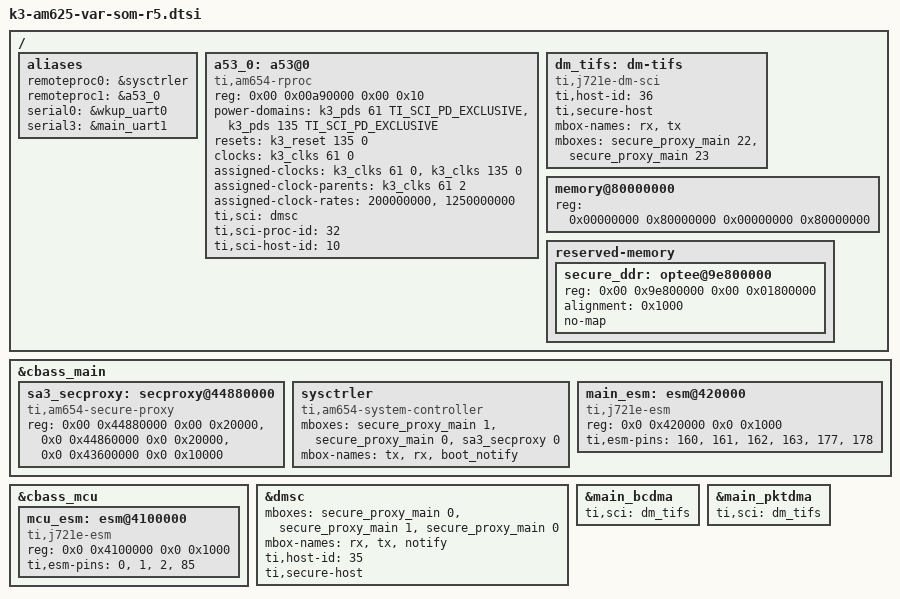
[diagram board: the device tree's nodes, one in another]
// SPDX-License-Identifier: GPL-2.0
/*
 * dtsi file for R5 SPL for VAR-SOM-AM62 and derivatives
 * Copyright (C) 2021-2022 Texas Instruments Incorporated - https://www.ti.com/
 * Copyright (C) 2023-2024 Variscite Ltd. - https://www.variscite.com/
 */

/ {
	aliases {
		remoteproc0 = &sysctrler;
		remoteproc1 = &a53_0;
		serial0 = &wkup_uart0;
		serial3 = &main_uart1;
	};

	a53_0: a53@0 {
		compatible = "ti,am654-rproc";
		reg = <0x00 0x00a90000 0x00 0x10>;
		power-domains = <&k3_pds 61 TI_SCI_PD_EXCLUSIVE>,
				<&k3_pds 135 TI_SCI_PD_EXCLUSIVE>;
		resets = <&k3_reset 135 0>;
		clocks = <&k3_clks 61 0>;
		assigned-clocks = <&k3_clks 61 0>, <&k3_clks 135 0>;
		assigned-clock-parents = <&k3_clks 61 2>;
		assigned-clock-rates = <200000000>, <1250000000>;
		ti,sci = <&dmsc>;
		ti,sci-proc-id = <32>;
		ti,sci-host-id = <10>;
		bootph-pre-ram;
	};

	dm_tifs: dm-tifs {
		compatible = "ti,j721e-dm-sci";
		ti,host-id = <36>;
		ti,secure-host;
		mbox-names = "rx", "tx";
		mboxes= <&secure_proxy_main 22>,
			<&secure_proxy_main 23>;
		bootph-pre-ram;
	};

	memory@80000000 {
		device_type = "memory";
		/* 2G RAM */
		reg = <0x00000000 0x80000000 0x00000000 0x80000000>;

		bootph-pre-ram;
	};

	reserved-memory {
		#address-cells = <2>;
		#size-cells = <2>;
		ranges;

		secure_ddr: optee@9e800000 {
			reg = <0x00 0x9e800000 0x00 0x01800000>; /* for OP-TEE */
			alignment = <0x1000>;
			no-map;
		};
	};
};

&cbass_main {
	sa3_secproxy: secproxy@44880000 {
		bootph-pre-ram;
		compatible = "ti,am654-secure-proxy";
		#mbox-cells = <1>;
		reg-names = "rt", "scfg", "target_data";
		reg = <0x00 0x44880000 0x00 0x20000>,
		      <0x0 0x44860000 0x0 0x20000>,
		      <0x0 0x43600000 0x0 0x10000>;
	};

	sysctrler: sysctrler {
		compatible = "ti,am654-system-controller";
		mboxes= <&secure_proxy_main 1>, <&secure_proxy_main 0>, <&sa3_secproxy 0>;
		mbox-names = "tx", "rx", "boot_notify";
		bootph-pre-ram;
	};

	main_esm: esm@420000 {
		compatible = "ti,j721e-esm";
		reg = <0x0 0x420000 0x0 0x1000>;
		ti,esm-pins = <160>, <161>, <162>, <163>, <177>, <178>;
		bootph-pre-ram;
	};
};

&cbass_mcu {
	mcu_esm: esm@4100000 {
		compatible = "ti,j721e-esm";
		reg = <0x0 0x4100000 0x0 0x1000>;
		ti,esm-pins = <0>, <1>, <2>, <85>;
		bootph-pre-ram;
	};
};

&dmsc {
	mboxes= <&secure_proxy_main 0>,
		<&secure_proxy_main 1>,
		<&secure_proxy_main 0>;
	mbox-names = "rx", "tx", "notify";
	ti,host-id = <35>;
	ti,secure-host;
};

&main_bcdma {
	ti,sci = <&dm_tifs>;
};

&main_pktdma {
	ti,sci = <&dm_tifs>;
};
